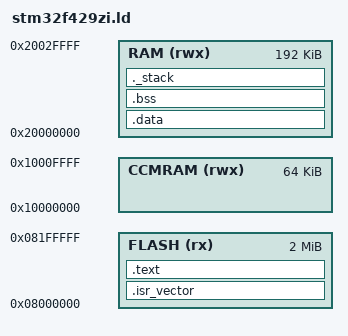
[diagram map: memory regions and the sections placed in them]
/* Linker script for STM32F429ZIT6 (2MB Flash, 256KB RAM) */

MEMORY
{
    FLASH (rx)  : ORIGIN = 0x08000000, LENGTH = 2048K
    RAM (rwx)   : ORIGIN = 0x20000000, LENGTH = 192K
    CCMRAM (rwx): ORIGIN = 0x10000000, LENGTH = 64K
}

_stack_size = 8K;

SECTIONS
{
    .isr_vector :
    {
        . = ALIGN(4);
        KEEP(*(.isr_vector))
        . = ALIGN(4);
    } > FLASH

    .text :
    {
        . = ALIGN(4);
        *(.text)
        *(.text*)
        *(.rodata)
        *(.rodata*)
        . = ALIGN(4);
        _etext = .;
    } > FLASH

    .data : AT(_etext)
    {
        . = ALIGN(4);
        _sdata = .;
        *(.data)
        *(.data*)
        . = ALIGN(4);
        _edata = .;
    } > RAM

    .bss :
    {
        . = ALIGN(4);
        _sbss = .;
        *(.bss)
        *(.bss*)
        *(COMMON)
        . = ALIGN(4);
        _ebss = .;
    } > RAM

    ._stack :
    {
        . = ALIGN(8);
        _sstack = .;
        . = . + _stack_size;
        . = ALIGN(8);
        _estack = .;
    } > RAM

    /DISCARD/ :
    {
        *(.ARM.exidx*)
        *(.ARM.attributes*)
    }
}

_end = .;
PROVIDE(end = .);
